# CY8C5888LTI_LP097 register map
File version: 0.1
CY8C58LP
Registers are 8-bit, read-write, no defined reset value unless marked. A register's access mark holds for its fields unless they carry their own. Offsets are from the block's base; lines under a group give offsets from that group; [hi:lo] are bit positions; {n}, {i} and the like mark numbered series; 'fields as' and 'values as' point back to an identical list; <NAME> marks a mode.

## Memory map
0x00000000 Status_Reg
0x00000000 UART

## Status_Reg
Base 0x00000000
0x40006565 Status_Reg_STATUS_REG
0x40006585 Status_Reg_MASK_REG
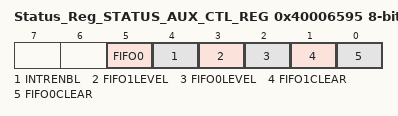
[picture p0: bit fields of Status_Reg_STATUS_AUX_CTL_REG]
0x40006595 Status_Reg_STATUS_AUX_CTL_REG
  [5] FIFO0 — FIFO0 clear
    1=ENABLED (Enable counter); 0=DISABLED (Disable counter)
  [4] INTRENBL — Enables or disables the Interrupt
    1=ENABLED (Interrupt enabled); 0=DISABLED (Interrupt disabled)
  [3] FIFO1LEVEL — FIFO level
    1=ENABLED (FIFO LVL: input mode: FIFO at least 1/2 empty; output mode: FIFO at least 1/2 full); 0=DISABLED (FIFO LVL: input mode: FIFO not full; output mode: FIFO not empty)
  [2] FIFO0LEVEL — FIFO level
    values as FIFO1LEVEL
  [1] FIFO1CLEAR — FIFO clear
    1=ENABLED (Clear FIFO state); 0=DISABLED (Normal FIFO operation)
  [0] FIFO0CLEAR — FIFO clear
    values as FIFO1CLEAR

## UART
Base 0x00000000
0x40006544 TX_UART_TX_DATA — TX Data Register
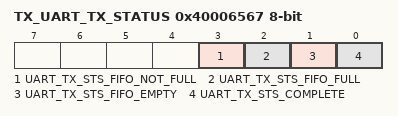
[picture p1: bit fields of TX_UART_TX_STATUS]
0x40006567 TX_UART_TX_STATUS — TX status register
  [3] UART_TX_STS_FIFO_NOT_FULL ro, [2] UART_TX_STS_FIFO_FULL ro, [1] UART_TX_STS_FIFO_EMPTY ro, [0] UART_TX_STS_COMPLETE ro
